# DEMO_STM32F103 register map
File version: 1.0
Demo device for the embedded-dev SVD decoder
Registers are 32-bit, read-write, reset 0x44444444 unless marked. A register's access mark holds for its fields unless they carry their own. Offsets are from the block's base; lines under a group give offsets from that group; [hi:lo] are bit positions; {n}, {i} and the like mark numbered series; 'fields as' and 'values as' point back to an identical list; <NAME> marks a mode.

## Memory map
0x40010800 GPIOA — General purpose I/O port A
0x40021000 RCC — Reset and clock control

## RCC — Reset and clock control
Base 0x40021000
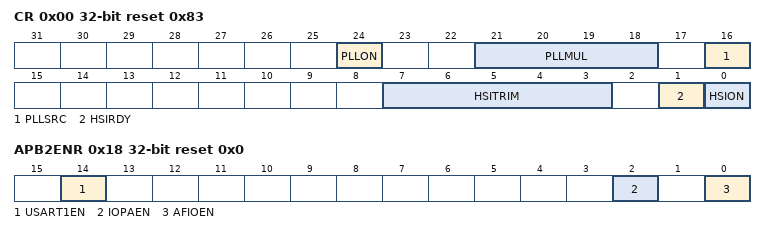
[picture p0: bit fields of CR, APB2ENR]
0x00 CR reset 0x83 — Clock control register
  [24] PLLON — PLL enable
  [21:18] PLLMUL — PLL multiplication factor
  [16] PLLSRC — PLL entry clock source
    0=HSI_DIV2; 1=HSE
  [7:3] HSITRIM — Internal high-speed clock trimming
  [1] HSIRDY ro — Internal high-speed clock ready flag
  [0] HSION — Internal high-speed clock enable
    0=OFF (HSI oscillator off); 1=ON (HSI oscillator on)
0x18 APB2ENR reset 0x0 — APB2 peripheral clock enable register
  [14] USART1EN — USART1 clock enable
  [2] IOPAEN — I/O port A clock enable
    0=DISABLED; 1=ENABLED
  [0] AFIOEN — Alternate function I/O clock enable

## GPIOA — General purpose I/O port A
Base 0x40010800
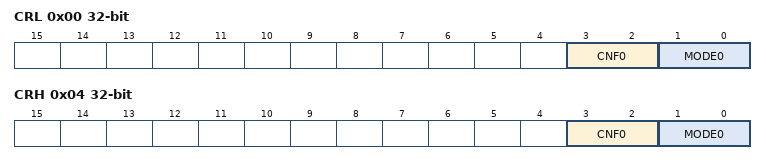
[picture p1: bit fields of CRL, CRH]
0x00 CRL — Port configuration register low
  [3:2] CNF0 — Port 0 configuration bits
  [1:0] MODE0 — Port 0 mode bits
    0=INPUT; 1=OUTPUT_10MHZ; 2=OUTPUT_2MHZ; 3=OUTPUT_50MHZ
0x04 CRH — Port configuration register high
  fields as CRL
